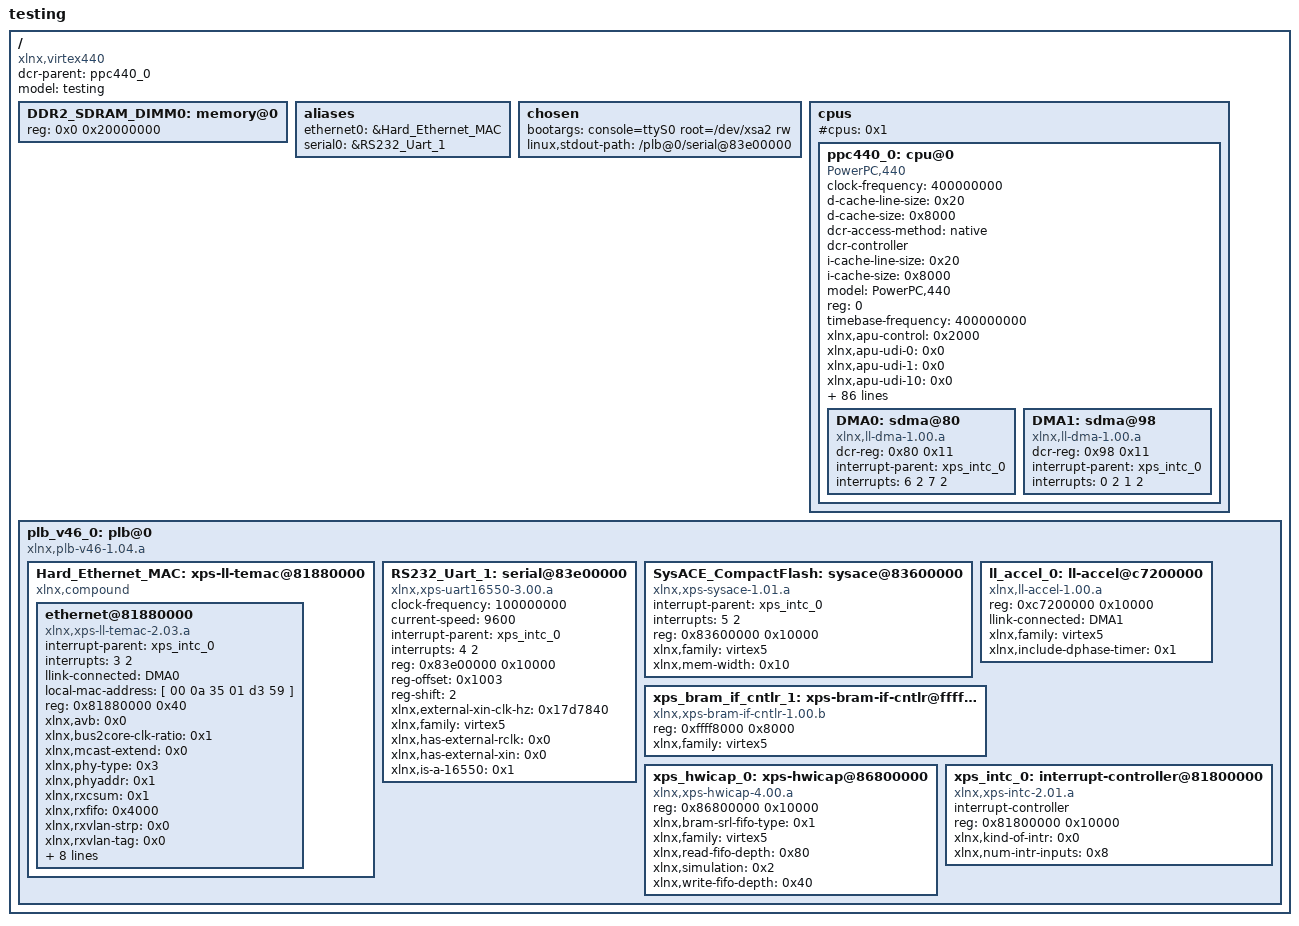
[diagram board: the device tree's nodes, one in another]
/*
 * Device Tree Generator version: 1.3
 *
 * (C) Copyright 2007-2008 Xilinx, Inc.
 * (C) Copyright 2007-2009 Michal Simek
 *
 * Michal SIMEK <monstr@monstr.eu>
 *
 * This program is free software; you can redistribute it and/or
 * modify it under the terms of the GNU General Public License as
 * published by the Free Software Foundation; either version 2 of
 * the License, or (at your option) any later version.
 *
 * This program is distributed in the hope that it will be useful,
 * but WITHOUT ANY WARRANTY; without even the implied warranty of
 * MERCHANTABILITY or FITNESS FOR A PARTICULAR PURPOSE. See the
 * GNU General Public License for more details.
 *
 * You should have received a copy of the GNU General Public License
 * along with this program; if not, write to the Free Software
 * Foundation, Inc., 59 Temple Place, Suite 330, Boston,
 * MA 02111-1307 USA
 *
 * CAUTION: This file is automatically generated by libgen.
 * Version: Xilinx EDK 12.1 EDK_MS1.53d
 *
 * XPS project directory: hybrid-os-attempt1
 */

/dts-v1/;
/ {
	#address-cells = <1>;
	#size-cells = <1>;
	compatible = "xlnx,virtex440", "xlnx,virtex";
	dcr-parent = <&ppc440_0>;
	model = "testing";
	DDR2_SDRAM_DIMM0: memory@0 {
		device_type = "memory";
		reg = < 0x0 0x20000000 >;
	} ;
	aliases {
		ethernet0 = &Hard_Ethernet_MAC;
		serial0 = &RS232_Uart_1;
	} ;
	chosen {
		bootargs = "console=ttyS0 root=/dev/xsa2 rw";
		linux,stdout-path = "/plb@0/serial@83e00000";
	} ;
	cpus {
		#address-cells = <1>;
		#cpus = <0x1>;
		#size-cells = <0>;
		ppc440_0: cpu@0 {
			#address-cells = <1>;
			#size-cells = <1>;
			clock-frequency = <400000000>;
			compatible = "PowerPC,440", "ibm,ppc440";
			d-cache-line-size = <0x20>;
			d-cache-size = <0x8000>;
			dcr-access-method = "native";
			dcr-controller ;
			device_type = "cpu";
			i-cache-line-size = <0x20>;
			i-cache-size = <0x8000>;
			model = "PowerPC,440";
			reg = <0>;
			timebase-frequency = <400000000>;
			xlnx,apu-control = <0x2000>;
			xlnx,apu-udi-0 = <0x0>;
			xlnx,apu-udi-1 = <0x0>;
			xlnx,apu-udi-10 = <0x0>;
			xlnx,apu-udi-11 = <0x0>;
			xlnx,apu-udi-12 = <0x0>;
			xlnx,apu-udi-13 = <0x0>;
			xlnx,apu-udi-14 = <0x0>;
			xlnx,apu-udi-15 = <0x0>;
			xlnx,apu-udi-2 = <0x0>;
			xlnx,apu-udi-3 = <0x0>;
			xlnx,apu-udi-4 = <0x0>;
			xlnx,apu-udi-5 = <0x0>;
			xlnx,apu-udi-6 = <0x0>;
			xlnx,apu-udi-7 = <0x0>;
			xlnx,apu-udi-8 = <0x0>;
			xlnx,apu-udi-9 = <0x0>;
			xlnx,dcr-autolock-enable = <0x1>;
			xlnx,dcu-rd-ld-cache-plb-prio = <0x0>;
			xlnx,dcu-rd-noncache-plb-prio = <0x0>;
			xlnx,dcu-rd-touch-plb-prio = <0x0>;
			xlnx,dcu-rd-urgent-plb-prio = <0x0>;
			xlnx,dcu-wr-flush-plb-prio = <0x0>;
			xlnx,dcu-wr-store-plb-prio = <0x0>;
			xlnx,dcu-wr-urgent-plb-prio = <0x0>;
			xlnx,dma0-control = <0x0>;
			xlnx,dma0-plb-prio = <0x0>;
			xlnx,dma0-rxchannelctrl = <0x1010000>;
			xlnx,dma0-rxirqtimer = <0x3ff>;
			xlnx,dma0-txchannelctrl = <0x1010000>;
			xlnx,dma0-txirqtimer = <0x3ff>;
			xlnx,dma1-control = <0x0>;
			xlnx,dma1-plb-prio = <0x0>;
			xlnx,dma1-rxchannelctrl = <0x1010000>;
			xlnx,dma1-rxirqtimer = <0x3ff>;
			xlnx,dma1-txchannelctrl = <0x1010000>;
			xlnx,dma1-txirqtimer = <0x3ff>;
			xlnx,dma2-control = <0x0>;
			xlnx,dma2-plb-prio = <0x0>;
			xlnx,dma2-rxchannelctrl = <0x1010000>;
			xlnx,dma2-rxirqtimer = <0x3ff>;
			xlnx,dma2-txchannelctrl = <0x1010000>;
			xlnx,dma2-txirqtimer = <0x3ff>;
			xlnx,dma3-control = <0x0>;
			xlnx,dma3-plb-prio = <0x0>;
			xlnx,dma3-rxchannelctrl = <0x1010000>;
			xlnx,dma3-rxirqtimer = <0x3ff>;
			xlnx,dma3-txchannelctrl = <0x1010000>;
			xlnx,dma3-txirqtimer = <0x3ff>;
			xlnx,endian-reset = <0x0>;
			xlnx,generate-plb-timespecs = <0x1>;
			xlnx,icu-rd-fetch-plb-prio = <0x0>;
			xlnx,icu-rd-spec-plb-prio = <0x0>;
			xlnx,icu-rd-touch-plb-prio = <0x0>;
			xlnx,interconnect-imask = <0xffffffff>;
			xlnx,mplb-allow-lock-xfer = <0x1>;
			xlnx,mplb-arb-mode = <0x0>;
			xlnx,mplb-awidth = <0x20>;
			xlnx,mplb-counter = <0x500>;
			xlnx,mplb-dwidth = <0x80>;
			xlnx,mplb-max-burst = <0x8>;
			xlnx,mplb-native-dwidth = <0x80>;
			xlnx,mplb-p2p = <0x0>;
			xlnx,mplb-prio-dcur = <0x2>;
			xlnx,mplb-prio-dcuw = <0x3>;
			xlnx,mplb-prio-icu = <0x4>;
			xlnx,mplb-prio-splb0 = <0x1>;
			xlnx,mplb-prio-splb1 = <0x0>;
			xlnx,mplb-read-pipe-enable = <0x1>;
			xlnx,mplb-sync-tattribute = <0x0>;
			xlnx,mplb-wdog-enable = <0x1>;
			xlnx,mplb-write-pipe-enable = <0x1>;
			xlnx,mplb-write-post-enable = <0x1>;
			xlnx,num-dma = <0x2>;
			xlnx,pir = <0xf>;
			xlnx,ppc440mc-addr-base = <0x0>;
			xlnx,ppc440mc-addr-high = <0x1fffffff>;
			xlnx,ppc440mc-arb-mode = <0x0>;
			xlnx,ppc440mc-bank-conflict-mask = <0xc00000>;
			xlnx,ppc440mc-control = <0xf810008f>;
			xlnx,ppc440mc-max-burst = <0x8>;
			xlnx,ppc440mc-prio-dcur = <0x2>;
			xlnx,ppc440mc-prio-dcuw = <0x3>;
			xlnx,ppc440mc-prio-icu = <0x4>;
			xlnx,ppc440mc-prio-splb0 = <0x1>;
			xlnx,ppc440mc-prio-splb1 = <0x0>;
			xlnx,ppc440mc-row-conflict-mask = <0x3ffe00>;
			xlnx,ppcdm-asyncmode = <0x0>;
			xlnx,ppcds-asyncmode = <0x0>;
			xlnx,user-reset = <0x0>;
			DMA0: sdma@80 {
				compatible = "xlnx,ll-dma-1.00.a";
				dcr-reg = < 0x80 0x11 >;
				interrupt-parent = <&xps_intc_0>;
				interrupts = < 6 2 7 2 >;
			} ;
			DMA1: sdma@98 {
				compatible = "xlnx,ll-dma-1.00.a";
				dcr-reg = < 0x98 0x11 >;
				interrupt-parent = <&xps_intc_0>;
				interrupts = < 0 2 1 2 >;
			} ;
		} ;
	} ;
	plb_v46_0: plb@0 {
		#address-cells = <1>;
		#size-cells = <1>;
		compatible = "xlnx,plb-v46-1.04.a", "xlnx,plb-v46-1.00.a", "simple-bus";
		ranges ;
		Hard_Ethernet_MAC: xps-ll-temac@81880000 {
			#address-cells = <1>;
			#size-cells = <1>;
			compatible = "xlnx,compound";
			ethernet@81880000 {
				compatible = "xlnx,xps-ll-temac-2.03.a", "xlnx,xps-ll-temac-1.00.a";
				device_type = "network";
				interrupt-parent = <&xps_intc_0>;
				interrupts = < 3 2 >;
				llink-connected = <&DMA0>;
				local-mac-address = [ 00 0a 35 01 d3 59 ];
				reg = < 0x81880000 0x40 >;
				xlnx,avb = <0x0>;
				xlnx,bus2core-clk-ratio = <0x1>;
				xlnx,mcast-extend = <0x0>;
				xlnx,phy-type = <0x3>;
				xlnx,phyaddr = <0x1>;
				xlnx,rxcsum = <0x1>;
				xlnx,rxfifo = <0x4000>;
				xlnx,rxvlan-strp = <0x0>;
				xlnx,rxvlan-tag = <0x0>;
				xlnx,rxvlan-tran = <0x0>;
				xlnx,stats = <0x0>;
				xlnx,temac-type = <0x0>;
				xlnx,txcsum = <0x1>;
				xlnx,txfifo = <0x4000>;
				xlnx,txvlan-strp = <0x0>;
				xlnx,txvlan-tag = <0x0>;
				xlnx,txvlan-tran = <0x0>;
			} ;
		} ;
		RS232_Uart_1: serial@83e00000 {
			clock-frequency = <100000000>;
			compatible = "xlnx,xps-uart16550-3.00.a", "ns16550";
			current-speed = <9600>;
			device_type = "serial";
			interrupt-parent = <&xps_intc_0>;
			interrupts = < 4 2 >;
			reg = < 0x83e00000 0x10000 >;
			reg-offset = <0x1003>;
			reg-shift = <2>;
			xlnx,external-xin-clk-hz = <0x17d7840>;
			xlnx,family = "virtex5";
			xlnx,has-external-rclk = <0x0>;
			xlnx,has-external-xin = <0x0>;
			xlnx,is-a-16550 = <0x1>;
		} ;
		SysACE_CompactFlash: sysace@83600000 {
			compatible = "xlnx,xps-sysace-1.01.a", "xlnx,xps-sysace-1.00.a";
			interrupt-parent = <&xps_intc_0>;
			interrupts = < 5 2 >;
			reg = < 0x83600000 0x10000 >;
			xlnx,family = "virtex5";
			xlnx,mem-width = <0x10>;
		} ;
		ll_accel_0: ll-accel@c7200000 {
			compatible = "xlnx,ll-accel-1.00.a";
			reg = < 0xc7200000 0x10000 >;
			llink-connected = <&DMA1>;
			xlnx,family = "virtex5";
			xlnx,include-dphase-timer = <0x1>;
		} ;
		xps_bram_if_cntlr_1: xps-bram-if-cntlr@ffff8000 {
			compatible = "xlnx,xps-bram-if-cntlr-1.00.b", "xlnx,xps-bram-if-cntlr-1.00.a";
			reg = < 0xffff8000 0x8000 >;
			xlnx,family = "virtex5";
		} ;
		xps_hwicap_0: xps-hwicap@86800000 {
			compatible = "xlnx,xps-hwicap-4.00.a", "xlnx,xps-hwicap-1.00.a";
			reg = < 0x86800000 0x10000 >;
			xlnx,bram-srl-fifo-type = <0x1>;
			xlnx,family = "virtex5";
			xlnx,read-fifo-depth = <0x80>;
			xlnx,simulation = <0x2>;
			xlnx,write-fifo-depth = <0x40>;
		} ;
		xps_intc_0: interrupt-controller@81800000 {
			#interrupt-cells = <0x2>;
			compatible = "xlnx,xps-intc-2.01.a", "xlnx,xps-intc-1.00.a";
			interrupt-controller ;
			reg = < 0x81800000 0x10000 >;
			xlnx,kind-of-intr = <0x0>;
			xlnx,num-intr-inputs = <0x8>;
		} ;
	} ;
}  ;
